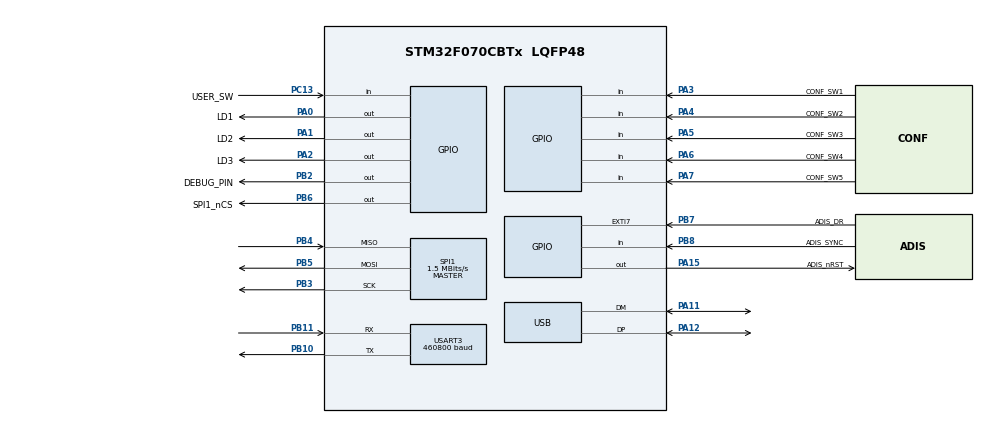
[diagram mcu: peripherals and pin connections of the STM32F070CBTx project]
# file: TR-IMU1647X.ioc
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Dma.Request0=USART3_RX
Dma.Request1=USART3_TX
Dma.USART3_RX.0.Direction=DMA_PERIPH_TO_MEMORY
Dma.USART3_RX.0.Instance=DMA1_Channel3
Dma.USART3_RX.0.MemDataAlignment=DMA_MDATAALIGN_BYTE
Dma.USART3_RX.0.MemInc=DMA_MINC_ENABLE
Dma.USART3_RX.0.Mode=DMA_CIRCULAR
Dma.USART3_RX.0.PeriphDataAlignment=DMA_PDATAALIGN_BYTE
Dma.USART3_RX.0.PeriphInc=DMA_PINC_DISABLE
Dma.USART3_RX.0.Priority=DMA_PRIORITY_HIGH
Dma.USART3_TX.1.Direction=DMA_MEMORY_TO_PERIPH
Dma.USART3_TX.1.Instance=DMA1_Channel2
Dma.USART3_TX.1.MemDataAlignment=DMA_MDATAALIGN_BYTE
Dma.USART3_TX.1.MemInc=DMA_MINC_ENABLE
Dma.USART3_TX.1.Mode=DMA_NORMAL
Dma.USART3_TX.1.PeriphDataAlignment=DMA_PDATAALIGN_BYTE
Dma.USART3_TX.1.PeriphInc=DMA_PINC_DISABLE
Dma.USART3_TX.1.Priority=DMA_PRIORITY_LOW
Mcu.Family=STM32F0
Mcu.Name=STM32F070CBTx
Mcu.Package=LQFP48
NVIC.DMA1_Channel2_3_IRQn=true\:0\:0\:false\:false\:true\:false\:true\:true
NVIC.EXTI4_15_IRQn=true\:2\:0\:true\:false\:true\:true\:true\:true
NVIC.USART3_4_IRQn=true\:1\:0\:true\:false\:true\:true\:true\:true
NVIC.USB_IRQn=true\:0\:0\:false\:false\:true\:false\:true\:true
PA0.GPIO_Label=LD1
PA0.GPIO_ModeDefaultOutputPP=GPIO_MODE_OUTPUT_OD
PA0.GPIO_PuPd=GPIO_NOPULL
PA0.GPIO_Speed=GPIO_SPEED_FREQ_HIGH
PA0.PinState=GPIO_PIN_SET
PA0.Signal=GPIO_Output
PA1.GPIO_Label=LD2
PA1.GPIO_ModeDefaultOutputPP=GPIO_MODE_OUTPUT_OD
PA1.GPIO_PuPd=GPIO_NOPULL
PA1.GPIO_Speed=GPIO_SPEED_FREQ_HIGH
PA1.PinState=GPIO_PIN_SET
PA1.Signal=GPIO_Output
PA11.Mode=Device
PA11.Signal=USB_DM
PA12.Mode=Device
PA12.Signal=USB_DP
PA13.Mode=Serial_Wire
PA13.Signal=SYS_SWDIO
PA14.Mode=Serial_Wire
PA14.Signal=SYS_SWCLK
PA15.GPIO_Label=ADIS_nRST
PA15.GPIO_Speed=GPIO_SPEED_FREQ_HIGH
PA15.PinState=GPIO_PIN_SET
PA15.Signal=GPIO_Output
PA2.GPIO_Label=LD3
PA2.GPIO_ModeDefaultOutputPP=GPIO_MODE_OUTPUT_OD
PA2.GPIO_PuPd=GPIO_NOPULL
PA2.GPIO_Speed=GPIO_SPEED_FREQ_HIGH
PA2.PinState=GPIO_PIN_SET
PA2.Signal=GPIO_Output
PA3.GPIO_Label=CONF_SW1
PA3.Signal=GPIO_Input
PA4.GPIO_Label=CONF_SW2
PA4.Signal=GPIO_Input
PA5.GPIO_Label=CONF_SW3
PA5.Signal=GPIO_Input
PA6.GPIO_Label=CONF_SW4
PA6.Signal=GPIO_Input
PA7.GPIO_Label=CONF_SW5
PA7.Signal=GPIO_Input
PB10.Mode=Asynchronous
PB10.Signal=USART3_TX
PB11.Mode=Asynchronous
PB11.Signal=USART3_RX
PB2.GPIO_Label=DEBUG_PIN
PB2.GPIO_Speed=GPIO_SPEED_FREQ_HIGH
PB2.Signal=GPIO_Output
PB3.Mode=Full_Duplex_Master
PB3.Signal=SPI1_SCK
PB4.Mode=Full_Duplex_Master
PB4.Signal=SPI1_MISO
PB5.Mode=Full_Duplex_Master
PB5.Signal=SPI1_MOSI
PB6.GPIO_FM6=SYSCFG_CFGR1_I2C_FMP_PB6
PB6.GPIO_Label=SPI1_nCS
PB6.GPIO_Speed=GPIO_SPEED_FREQ_HIGH
PB6.PinState=GPIO_PIN_SET
PB6.Signal=GPIO_Output
PB7.GPIO_Label=ADIS_DR
PB7.GPIO_ModeDefaultEXTI=GPIO_MODE_IT_RISING
PB7.GPIO_PuPd=GPIO_PULLUP
PB7.Signal=GPXTI7
PB8.GPIO_Label=ADIS_SYNC
PB8.Signal=GPIO_Input
PC13.GPIO_Label=USER_SW
PC13.Signal=GPIO_Input
PF0-OSC_IN.Mode=HSE-External-Oscillator
PF0-OSC_IN.Signal=RCC_OSC_IN
PF1-OSC_OUT.Mode=HSE-External-Oscillator
PF1-OSC_OUT.Signal=RCC_OSC_OUT
ProjectManager.HeapSize=0x400
ProjectManager.StackSize=0x400
ProjectManager.TargetToolchain=STM32CubeIDE
RCC.AHBFreq_Value=48000000
RCC.APB1Freq_Value=48000000
RCC.APB1TimFreq_Value=48000000
RCC.HCLKFreq_Value=48000000
RCC.PLLMUL=RCC_PLL_MUL6
RCC.SYSCLKFreq_VALUE=48000000
RCC.SYSCLKSource=RCC_SYSCLKSOURCE_PLLCLK
SPI1.BaudRatePrescaler=SPI_BAUDRATEPRESCALER_32
SPI1.CLKPhase=SPI_PHASE_2EDGE
SPI1.CLKPolarity=SPI_POLARITY_HIGH
SPI1.CalculateBaudRate=1.5 MBits/s
SPI1.DataSize=SPI_DATASIZE_16BIT
SPI1.Direction=SPI_DIRECTION_2LINES
SPI1.Mode=SPI_MODE_MASTER
SPI1.VirtualType=VM_MASTER
USART3.BaudRate=460800
USART3.VirtualMode-Asynchronous=VM_ASYNC
USB_DEVICE.CLASS_NAME_FS=CDC
USB_DEVICE.VirtualMode=Cdc
USB_DEVICE.VirtualModeFS=Cdc_FS
VP_IWDG_VS_IWDG.Mode=IWDG_Activate
VP_USB_DEVICE_VS_USB_DEVICE_CDC_FS.Mode=CDC_FS
board=custom

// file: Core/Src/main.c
/* USER CODE BEGIN Header */
/**
  ******************************************************************************
  * @file           : main.c
  * @brief          : Main program body
  ******************************************************************************
  * @attention
  *
  * Copyright (c) 2023 STMicroelectronics.
  * All rights reserved.
  *
  * This software is licensed under terms that can be found in the LICENSE file
  * in the root directory of this software component.
  * If no LICENSE file comes with this software, it is provided AS-IS.
  *
  ******************************************************************************
  */
/* USER CODE END Header */
#include "main.h"
#include "usb_device.h"

/* USER CODE BEGIN Includes */
#include "libraries.h"
/* USER CODE END Includes */

void SystemClock_Config(void);
static void MX_GPIO_Init(void);
static void MX_DMA_Init(void);
static void MX_SPI1_Init(void);
static void MX_USART3_UART_Init(void);

int main(void)
{

  /* MCU Configuration--------------------------------------------------------*/

  /* Reset of all peripherals, Initializes the Flash interface and the Systick. */
  HAL_Init();

  /* Configure the system clock */
  SystemClock_Config();

  /* Initialize all configured peripherals */
  MX_GPIO_Init();
  MX_DMA_Init();
  MX_USB_DEVICE_Init();
  MX_SPI1_Init();
  MX_USART3_UART_Init();
  /* USER CODE BEGIN 2 */
  ExtiStop();
  setup();
  /* USER CODE END 2 */

  /* Infinite loop */
  /* USER CODE BEGIN WHILE */
  while (1)
  {
    loop();
    /* USER CODE END WHILE */

  }
}

void SystemClock_Config(void)
{
  LL_FLASH_SetLatency(LL_FLASH_LATENCY_1);
  while(LL_FLASH_GetLatency() != LL_FLASH_LATENCY_1)
  {
  }
  LL_RCC_HSE_Enable();

   /* Wait till HSE is ready */
  while(LL_RCC_HSE_IsReady() != 1)
  {

  }
  LL_RCC_LSI_Enable();

   /* Wait till LSI is ready */
  while(LL_RCC_LSI_IsReady() != 1)
  {

  }
  LL_RCC_PLL_ConfigDomain_SYS(LL_RCC_PLLSOURCE_HSE, LL_RCC_PLL_MUL_6, LL_RCC_PREDIV_DIV_1);
  LL_RCC_PLL_Enable();

   /* Wait till PLL is ready */
  while(LL_RCC_PLL_IsReady() != 1)
  {

  }
  LL_RCC_SetAHBPrescaler(LL_RCC_SYSCLK_DIV_1);
  LL_RCC_SetAPB1Prescaler(LL_RCC_APB1_DIV_1);
  LL_RCC_SetSysClkSource(LL_RCC_SYS_CLKSOURCE_PLL);

   /* Wait till System clock is ready */
  while(LL_RCC_GetSysClkSource() != LL_RCC_SYS_CLKSOURCE_STATUS_PLL)
  {

  }
  LL_SetSystemCoreClock(48000000);

   /* Update the time base */
  if (HAL_InitTick (TICK_INT_PRIORITY) != HAL_OK)
  {
    Error_Handler();
  }
  LL_RCC_SetUSBClockSource(LL_RCC_USB_CLKSOURCE_PLL);
}

static void MX_SPI1_Init(void)
{

  LL_SPI_InitTypeDef SPI_InitStruct = {0};

  LL_GPIO_InitTypeDef GPIO_InitStruct = {0};

  /* Peripheral clock enable */
  LL_APB1_GRP2_EnableClock(LL_APB1_GRP2_PERIPH_SPI1);

  LL_AHB1_GRP1_EnableClock(LL_AHB1_GRP1_PERIPH_GPIOB);
  /**SPI1 GPIO Configuration
  PB3   ------> SPI1_SCK
  PB4   ------> SPI1_MISO
  PB5   ------> SPI1_MOSI
  */
  GPIO_InitStruct.Pin = LL_GPIO_PIN_3;
  GPIO_InitStruct.Mode = LL_GPIO_MODE_ALTERNATE;
  GPIO_InitStruct.Speed = LL_GPIO_SPEED_FREQ_HIGH;
  GPIO_InitStruct.OutputType = LL_GPIO_OUTPUT_PUSHPULL;
  GPIO_InitStruct.Pull = LL_GPIO_PULL_NO;
  GPIO_InitStruct.Alternate = LL_GPIO_AF_0;
  LL_GPIO_Init(GPIOB, &GPIO_InitStruct);

  GPIO_InitStruct.Pin = LL_GPIO_PIN_4;
  GPIO_InitStruct.Mode = LL_GPIO_MODE_ALTERNATE;
  GPIO_InitStruct.Speed = LL_GPIO_SPEED_FREQ_HIGH;
  GPIO_InitStruct.OutputType = LL_GPIO_OUTPUT_PUSHPULL;
  GPIO_InitStruct.Pull = LL_GPIO_PULL_NO;
  GPIO_InitStruct.Alternate = LL_GPIO_AF_0;
  LL_GPIO_Init(GPIOB, &GPIO_InitStruct);

  GPIO_InitStruct.Pin = LL_GPIO_PIN_5;
  GPIO_InitStruct.Mode = LL_GPIO_MODE_ALTERNATE;
  GPIO_InitStruct.Speed = LL_GPIO_SPEED_FREQ_HIGH;
  GPIO_InitStruct.OutputType = LL_GPIO_OUTPUT_PUSHPULL;
  GPIO_InitStruct.Pull = LL_GPIO_PULL_NO;
  GPIO_InitStruct.Alternate = LL_GPIO_AF_0;
  LL_GPIO_Init(GPIOB, &GPIO_InitStruct);

  /* SPI1 parameter configuration*/
  SPI_InitStruct.TransferDirection = LL_SPI_FULL_DUPLEX;
  SPI_InitStruct.Mode = LL_SPI_MODE_MASTER;
  SPI_InitStruct.DataWidth = LL_SPI_DATAWIDTH_16BIT;
  SPI_InitStruct.ClockPolarity = LL_SPI_POLARITY_HIGH;
  SPI_InitStruct.ClockPhase = LL_SPI_PHASE_2EDGE;
  SPI_InitStruct.NSS = LL_SPI_NSS_SOFT;
  SPI_InitStruct.BaudRate = LL_SPI_BAUDRATEPRESCALER_DIV32;
  SPI_InitStruct.BitOrder = LL_SPI_MSB_FIRST;
  SPI_InitStruct.CRCCalculation = LL_SPI_CRCCALCULATION_DISABLE;
  SPI_InitStruct.CRCPoly = 7;
  LL_SPI_Init(SPI1, &SPI_InitStruct);
  LL_SPI_SetStandard(SPI1, LL_SPI_PROTOCOL_MOTOROLA);
  LL_SPI_DisableNSSPulseMgt(SPI1);

}

static void MX_USART3_UART_Init(void)
{

  LL_USART_InitTypeDef USART_InitStruct = {0};

  LL_GPIO_InitTypeDef GPIO_InitStruct = {0};

  /* Peripheral clock enable */
  LL_APB1_GRP1_EnableClock(LL_APB1_GRP1_PERIPH_USART3);

  LL_AHB1_GRP1_EnableClock(LL_AHB1_GRP1_PERIPH_GPIOB);
  /**USART3 GPIO Configuration
  PB10   ------> USART3_TX
  PB11   ------> USART3_RX
  */
  GPIO_InitStruct.Pin = LL_GPIO_PIN_10;
  GPIO_InitStruct.Mode = LL_GPIO_MODE_ALTERNATE;
  GPIO_InitStruct.Speed = LL_GPIO_SPEED_FREQ_HIGH;
  GPIO_InitStruct.OutputType = LL_GPIO_OUTPUT_PUSHPULL;
  GPIO_InitStruct.Pull = LL_GPIO_PULL_NO;
  GPIO_InitStruct.Alternate = LL_GPIO_AF_4;
  LL_GPIO_Init(GPIOB, &GPIO_InitStruct);

  GPIO_InitStruct.Pin = LL_GPIO_PIN_11;
  GPIO_InitStruct.Mode = LL_GPIO_MODE_ALTERNATE;
  GPIO_InitStruct.Speed = LL_GPIO_SPEED_FREQ_HIGH;
  GPIO_InitStruct.OutputType = LL_GPIO_OUTPUT_PUSHPULL;
  GPIO_InitStruct.Pull = LL_GPIO_PULL_NO;
  GPIO_InitStruct.Alternate = LL_GPIO_AF_4;
  LL_GPIO_Init(GPIOB, &GPIO_InitStruct);

  /* USART3 DMA Init */

  /* USART3_RX Init */
  LL_DMA_SetDataTransferDirection(DMA1, LL_DMA_CHANNEL_3, LL_DMA_DIRECTION_PERIPH_TO_MEMORY);

  LL_DMA_SetChannelPriorityLevel(DMA1, LL_DMA_CHANNEL_3, LL_DMA_PRIORITY_HIGH);

  LL_DMA_SetMode(DMA1, LL_DMA_CHANNEL_3, LL_DMA_MODE_CIRCULAR);

  LL_DMA_SetPeriphIncMode(DMA1, LL_DMA_CHANNEL_3, LL_DMA_PERIPH_NOINCREMENT);

  LL_DMA_SetMemoryIncMode(DMA1, LL_DMA_CHANNEL_3, LL_DMA_MEMORY_INCREMENT);

  LL_DMA_SetPeriphSize(DMA1, LL_DMA_CHANNEL_3, LL_DMA_PDATAALIGN_BYTE);

  LL_DMA_SetMemorySize(DMA1, LL_DMA_CHANNEL_3, LL_DMA_MDATAALIGN_BYTE);

  LL_SYSCFG_SetRemapDMA_USART(LL_SYSCFG_USART3_RMP_DMA1CH32);

  /* USART3_TX Init */
  LL_DMA_SetDataTransferDirection(DMA1, LL_DMA_CHANNEL_2, LL_DMA_DIRECTION_MEMORY_TO_PERIPH);

  LL_DMA_SetChannelPriorityLevel(DMA1, LL_DMA_CHANNEL_2, LL_DMA_PRIORITY_LOW);

  LL_DMA_SetMode(DMA1, LL_DMA_CHANNEL_2, LL_DMA_MODE_NORMAL);

  LL_DMA_SetPeriphIncMode(DMA1, LL_DMA_CHANNEL_2, LL_DMA_PERIPH_NOINCREMENT);

  LL_DMA_SetMemoryIncMode(DMA1, LL_DMA_CHANNEL_2, LL_DMA_MEMORY_INCREMENT);

  LL_DMA_SetPeriphSize(DMA1, LL_DMA_CHANNEL_2, LL_DMA_PDATAALIGN_BYTE);

  LL_DMA_SetMemorySize(DMA1, LL_DMA_CHANNEL_2, LL_DMA_MDATAALIGN_BYTE);

  LL_SYSCFG_SetRemapDMA_USART(LL_SYSCFG_USART3_RMP_DMA1CH32);

  /* USART3 interrupt Init */
  NVIC_SetPriority(USART3_4_IRQn, 1);
  NVIC_EnableIRQ(USART3_4_IRQn);

  USART_InitStruct.BaudRate = 460800;
  USART_InitStruct.DataWidth = LL_USART_DATAWIDTH_8B;
  USART_InitStruct.StopBits = LL_USART_STOPBITS_1;
  USART_InitStruct.Parity = LL_USART_PARITY_NONE;
  USART_InitStruct.TransferDirection = LL_USART_DIRECTION_TX_RX;
  USART_InitStruct.HardwareFlowControl = LL_USART_HWCONTROL_NONE;
  USART_InitStruct.OverSampling = LL_USART_OVERSAMPLING_16;
  LL_USART_Init(USART3, &USART_InitStruct);
  LL_USART_DisableIT_CTS(USART3);
  LL_USART_ConfigAsyncMode(USART3);
  LL_USART_Enable(USART3);

}

static void MX_DMA_Init(void)
{

  /* Init with LL driver */
  /* DMA controller clock enable */
  LL_AHB1_GRP1_EnableClock(LL_AHB1_GRP1_PERIPH_DMA1);

  /* DMA interrupt init */
  /* DMA1_Channel2_3_IRQn interrupt configuration */
  NVIC_SetPriority(DMA1_Channel2_3_IRQn, 0);
  NVIC_EnableIRQ(DMA1_Channel2_3_IRQn);

}

static void MX_GPIO_Init(void)
{
  LL_EXTI_InitTypeDef EXTI_InitStruct = {0};
  LL_GPIO_InitTypeDef GPIO_InitStruct = {0};

  /* GPIO Ports Clock Enable */
  LL_AHB1_GRP1_EnableClock(LL_AHB1_GRP1_PERIPH_GPIOC);
  LL_AHB1_GRP1_EnableClock(LL_AHB1_GRP1_PERIPH_GPIOF);
  LL_AHB1_GRP1_EnableClock(LL_AHB1_GRP1_PERIPH_GPIOA);
  LL_AHB1_GRP1_EnableClock(LL_AHB1_GRP1_PERIPH_GPIOB);

  /**/
  LL_GPIO_SetOutputPin(LD1_GPIO_Port, LD1_Pin);

  /**/
  LL_GPIO_SetOutputPin(LD2_GPIO_Port, LD2_Pin);

  /**/
  LL_GPIO_SetOutputPin(LD3_GPIO_Port, LD3_Pin);

  /**/
  LL_GPIO_SetOutputPin(ADIS_nRST_GPIO_Port, ADIS_nRST_Pin);

  /**/
  LL_GPIO_SetOutputPin(SPI1_nCS_GPIO_Port, SPI1_nCS_Pin);

  /**/
  LL_GPIO_ResetOutputPin(DEBUG_PIN_GPIO_Port, DEBUG_PIN_Pin);

  /**/
  GPIO_InitStruct.Pin = USER_SW_Pin;
  GPIO_InitStruct.Mode = LL_GPIO_MODE_INPUT;
  GPIO_InitStruct.Pull = LL_GPIO_PULL_NO;
  LL_GPIO_Init(USER_SW_GPIO_Port, &GPIO_InitStruct);

  /**/
  GPIO_InitStruct.Pin = LD1_Pin;
  GPIO_InitStruct.Mode = LL_GPIO_MODE_OUTPUT;
  GPIO_InitStruct.Speed = LL_GPIO_SPEED_FREQ_HIGH;
  GPIO_InitStruct.OutputType = LL_GPIO_OUTPUT_OPENDRAIN;
  GPIO_InitStruct.Pull = LL_GPIO_PULL_NO;
  LL_GPIO_Init(LD1_GPIO_Port, &GPIO_InitStruct);

  /**/
  GPIO_InitStruct.Pin = LD2_Pin;
  GPIO_InitStruct.Mode = LL_GPIO_MODE_OUTPUT;
  GPIO_InitStruct.Speed = LL_GPIO_SPEED_FREQ_HIGH;
  GPIO_InitStruct.OutputType = LL_GPIO_OUTPUT_OPENDRAIN;
  GPIO_InitStruct.Pull = LL_GPIO_PULL_NO;
  LL_GPIO_Init(LD2_GPIO_Port, &GPIO_InitStruct);

  /**/
  GPIO_InitStruct.Pin = LD3_Pin;
  GPIO_InitStruct.Mode = LL_GPIO_MODE_OUTPUT;
  GPIO_InitStruct.Speed = LL_GPIO_SPEED_FREQ_HIGH;
  GPIO_InitStruct.OutputType = LL_GPIO_OUTPUT_OPENDRAIN;
  GPIO_InitStruct.Pull = LL_GPIO_PULL_NO;
  LL_GPIO_Init(LD3_GPIO_Port, &GPIO_InitStruct);

  /**/
  GPIO_InitStruct.Pin = CONF_SW1_Pin;
  GPIO_InitStruct.Mode = LL_GPIO_MODE_INPUT;
  GPIO_InitStruct.Pull = LL_GPIO_PULL_NO;
  LL_GPIO_Init(CONF_SW1_GPIO_Port, &GPIO_InitStruct);

  /**/
  GPIO_InitStruct.Pin = CONF_SW2_Pin;
  GPIO_InitStruct.Mode = LL_GPIO_MODE_INPUT;
  GPIO_InitStruct.Pull = LL_GPIO_PULL_NO;
  LL_GPIO_Init(CONF_SW2_GPIO_Port, &GPIO_InitStruct);

  /**/
  GPIO_InitStruct.Pin = CONF_SW3_Pin;
  GPIO_InitStruct.Mode = LL_GPIO_MODE_INPUT;
  GPIO_InitStruct.Pull = LL_GPIO_PULL_NO;
  LL_GPIO_Init(CONF_SW3_GPIO_Port, &GPIO_InitStruct);

  /**/
  GPIO_InitStruct.Pin = CONF_SW4_Pin;
  GPIO_InitStruct.Mode = LL_GPIO_MODE_INPUT;
  GPIO_InitStruct.Pull = LL_GPIO_PULL_NO;
  LL_GPIO_Init(CONF_SW4_GPIO_Port, &GPIO_InitStruct);

  /**/
  GPIO_InitStruct.Pin = CONF_SW5_Pin;
  GPIO_InitStruct.Mode = LL_GPIO_MODE_INPUT;
  GPIO_InitStruct.Pull = LL_GPIO_PULL_NO;
  LL_GPIO_Init(CONF_SW5_GPIO_Port, &GPIO_InitStruct);

  /**/
  GPIO_InitStruct.Pin = DEBUG_PIN_Pin;
  GPIO_InitStruct.Mode = LL_GPIO_MODE_OUTPUT;
  GPIO_InitStruct.Speed = LL_GPIO_SPEED_FREQ_HIGH;
  GPIO_InitStruct.OutputType = LL_GPIO_OUTPUT_PUSHPULL;
  GPIO_InitStruct.Pull = LL_GPIO_PULL_NO;
  LL_GPIO_Init(DEBUG_PIN_GPIO_Port, &GPIO_InitStruct);

  /**/
  GPIO_InitStruct.Pin = ADIS_nRST_Pin;
  GPIO_InitStruct.Mode = LL_GPIO_MODE_OUTPUT;
  GPIO_InitStruct.Speed = LL_GPIO_SPEED_FREQ_HIGH;
  GPIO_InitStruct.OutputType = LL_GPIO_OUTPUT_PUSHPULL;
  GPIO_InitStruct.Pull = LL_GPIO_PULL_NO;
  LL_GPIO_Init(ADIS_nRST_GPIO_Port, &GPIO_InitStruct);

  /**/
  GPIO_InitStruct.Pin = SPI1_nCS_Pin;
  GPIO_InitStruct.Mode = LL_GPIO_MODE_OUTPUT;
  GPIO_InitStruct.Speed = LL_GPIO_SPEED_FREQ_HIGH;
  GPIO_InitStruct.OutputType = LL_GPIO_OUTPUT_PUSHPULL;
  GPIO_InitStruct.Pull = LL_GPIO_PULL_NO;
  LL_GPIO_Init(SPI1_nCS_GPIO_Port, &GPIO_InitStruct);

  /**/
  GPIO_InitStruct.Pin = ADIS_SYNC_Pin;
  GPIO_InitStruct.Mode = LL_GPIO_MODE_INPUT;
  GPIO_InitStruct.Pull = LL_GPIO_PULL_NO;
  LL_GPIO_Init(ADIS_SYNC_GPIO_Port, &GPIO_InitStruct);

  /**/
  LL_SYSCFG_EnableFastModePlus(SYSCFG_CFGR1_I2C_FMP_PB6);

  /**/
  LL_SYSCFG_SetEXTISource(LL_SYSCFG_EXTI_PORTB, LL_SYSCFG_EXTI_LINE7);

  /**/
  LL_GPIO_SetPinPull(ADIS_DR_GPIO_Port, ADIS_DR_Pin, LL_GPIO_PULL_UP);

  /**/
  LL_GPIO_SetPinMode(ADIS_DR_GPIO_Port, ADIS_DR_Pin, LL_GPIO_MODE_INPUT);

  /**/
  EXTI_InitStruct.Line_0_31 = LL_EXTI_LINE_7;
  EXTI_InitStruct.LineCommand = ENABLE;
  EXTI_InitStruct.Mode = LL_EXTI_MODE_IT;
  EXTI_InitStruct.Trigger = LL_EXTI_TRIGGER_RISING;
  LL_EXTI_Init(&EXTI_InitStruct);

  /* EXTI interrupt init*/
  NVIC_SetPriority(EXTI4_15_IRQn, 2);
  NVIC_EnableIRQ(EXTI4_15_IRQn);

}

void Error_Handler(void)
{
  __disable_irq();
  while (1)
  {
  }
}
